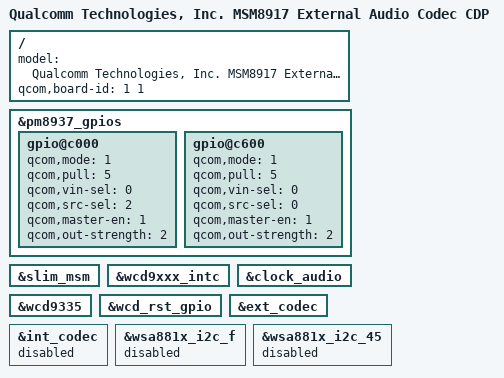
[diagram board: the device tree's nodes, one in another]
/*
 * Copyright (c) 2018, The Linux Foundation. All rights reserved.
 *
 * This program is free software; you can redistribute it and/or modify
 * it under the terms of the GNU General Public License version 2 and
 * only version 2 as published by the Free Software Foundation.
 *
 * This program is distributed in the hope that it will be useful,
 * but WITHOUT ANY WARRANTY; without even the implied warranty of
 * MERCHANTABILITY or FITNESS FOR A PARTICULAR PURPOSE.  See the
 * GNU General Public License for more details.
 */

/dts-v1/;
/plugin/;

#include "msm8917-cdp.dtsi"

/ {
	model = "Qualcomm Technologies, Inc. MSM8917 External Audio Codec CDP";
	qcom,board-id = <1 1>;
};

&pm8937_gpios {
	gpio@c000 {
		status = "ok";
		qcom,mode = <1>;
		qcom,pull = <5>;
		qcom,vin-sel = <0>;
		qcom,src-sel = <2>;
		qcom,master-en = <1>;
		qcom,out-strength = <2>;
	};

	gpio@c600 {
		status = "ok";
		qcom,mode = <1>;
		qcom,pull = <5>;
		qcom,vin-sel = <0>;
		qcom,src-sel = <0>;
		qcom,master-en = <1>;
		qcom,out-strength = <2>;
	};
};

&slim_msm {
	status = "okay";
};

&wcd9xxx_intc {
	status = "okay";
};

&clock_audio {
	status = "okay";
};

&wcd9335 {
	status = "okay";
};

&wcd_rst_gpio {
	status = "okay";
};

&ext_codec {
	status = "okay";
};

&int_codec {
	status = "disabled";
};

&wsa881x_i2c_f {
	status = "disabled";
};

&wsa881x_i2c_45 {
	status = "disabled";
};
